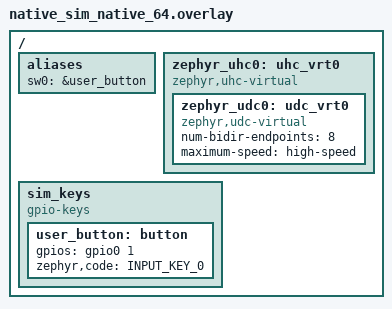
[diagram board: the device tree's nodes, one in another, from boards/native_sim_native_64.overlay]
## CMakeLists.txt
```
# hid8k-sim: hid8k's USB device code on native_sim, against Zephyr's own USB host stack on the
# virtual bus (drivers/usb/udc/udc_virtual.c, drivers/usb/uhc/uhc_virtual.c). See README.md.
# SPDX-License-Identifier: Apache-2.0

cmake_minimum_required(VERSION 3.20.0)

get_filename_component(HID8K_DIR ${CMAKE_CURRENT_LIST_DIR}/.. ABSOLUTE)

# The board's prj.conf first, so the simulation runs the firmware's own configuration (queue
# depth, HID buffer count, event queue sizes, logging), then the simulation's additions.
if(NOT DEFINED CONF_FILE)
  set(CONF_FILE "${HID8K_DIR}/prj.conf;${CMAKE_CURRENT_LIST_DIR}/prj.conf")
endif()

find_package(Zephyr REQUIRED HINTS $ENV{ZEPHYR_BASE})
project(hid8k_sim)

# The firmware, unchanged: the same four files the board build compiles.
target_sources(app PRIVATE
  ${HID8K_DIR}/src/main.c
  ${HID8K_DIR}/src/hid8k.c
  ${HID8K_DIR}/src/cdc_console.c
  ${HID8K_DIR}/src/usb_device.c
)

# The host side: two small class drivers for Zephyr's host stack and the test.
target_sources(app PRIVATE
  src/host_hid.c
  src/host_cdc.c
  src/sim_main.c
)

target_include_directories(app PRIVATE
  ${HID8K_DIR}/src
  ${ZEPHYR_BASE}/subsys/usb/host
  ${ZEPHYR_BASE}/drivers/usb/uhc
)

# The same warnings as the board build (see ../CMakeLists.txt).
target_compile_options(app PRIVATE -Wextra -Wshadow -Wno-type-limits)

if(CONFIG_HID8K_SIM_UHC_HS_FIX)
  # A copy of Zephyr v4.5.0's virtual host controller with its microframe timer kept after a bus
  # reset (drivers/uhc_virtual_hs.c says what changed and why).
  target_sources(app PRIVATE drivers/uhc_virtual_hs.c)
  target_include_directories(app PRIVATE ${ZEPHYR_BASE}/drivers/usb)
  # Zephyr's code, built with Zephyr's warnings, not this app's stricter -Wextra.
  set_source_files_properties(drivers/uhc_virtual_hs.c PROPERTIES COMPILE_OPTIONS
    "-Wno-extra;-Wno-unused-parameter")
endif()
```

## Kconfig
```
# hid8k-sim: the simulation's own options. The firmware's options follow (../Kconfig).
# SPDX-License-Identifier: Apache-2.0

menu "hid8k simulation (native_sim)"

config HID8K_SIM_UHC_HS_FIX
	bool "Build the simulation's copy of the virtual host controller (125 us microframes)"
	help
	  Zephyr v4.5.0's virtual host controller starts its SOF timer at
	  125 us when a high-speed device connects, but every bus reset,
	  resume and SOF enable restarts it at 1 ms, and the host stack resets
	  the bus as the first step of enumeration. So with the stock driver a
	  high-speed device is polled once per 1 ms frame. With this option the
	  simulation builds drivers/uhc_virtual_hs.c instead (set
	  CONFIG_UHC_VIRTUAL=n with it: hs_fix.conf does both), which keeps the
	  period the device's speed calls for.

config HID8K_SIM_STREAM_S
	int "Seconds of undisturbed stream to check and capture"
	default 3
	help
	  The run-time option --hid8k_stream_s overrides it.

config HID8K_SIM_HOST_XFERS
	int "Interrupt IN transfers the host keeps queued on the HID endpoint"
	range 1 2
	default 1
	help
	  1, like Linux usbhid's single interrupt URB. 2 shows a limitation of
	  the virtual host controller: it schedules one transfer per endpoint
	  per frame and only advances the start frame of the one it schedules,
	  so a second transfer queued on the same endpoint misses its start
	  frame and waits until the 16-bit frame counter comes round again.

endmenu

rsource "../Kconfig"
```

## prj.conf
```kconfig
# hid8k-sim: added to ../prj.conf (the board's), see CMakeLists.txt.

CONFIG_HID8K_SIM=y

# Zephyr's USB host stack on the virtual host controller (devicetree: boards/).
CONFIG_USB_HOST_STACK=y
CONFIG_UHC_DRIVER=y
CONFIG_UHC_XFER_COUNT=32
CONFIG_UHC_BUF_COUNT=32
CONFIG_UHC_BUF_POOL_SIZE=8192
CONFIG_UVB_MAX_MESSAGES=64
CONFIG_USBH_STACK_SIZE=2048

# A 125 us timer needs a tick finer than native_sim's default 10 ms: one tick per microsecond,
# as Zephyr's own USB host test sets (tests/subsys/usb/host/Kconfig).
CONFIG_SYS_CLOCK_TICKS_PER_SEC=1000000

# The simulation checks what the board build leaves unchecked.
CONFIG_ASSERT=y

# The button (gpio-keys on the emulated GPIO, boards/).
CONFIG_GPIO_EMUL=y

# Logs go to stdout, deferred as on the board (native_sim would default to immediate); keep the
# host stack quiet unless something is wrong.
CONFIG_LOG_MODE_DEFERRED=y
CONFIG_USBH_LOG_LEVEL_WRN=y
CONFIG_UHC_DRIVER_LOG_LEVEL_WRN=y

# Run as fast as the host allows, not in real time (native_sim's default for a non-test app).
CONFIG_NATIVE_SIM_SLOWDOWN_TO_REAL_TIME=n
```

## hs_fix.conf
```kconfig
# hid8k-sim with 125 us microframes: build the simulation's copy of the virtual host controller
# (drivers/uhc_virtual_hs.c) instead of Zephyr's. Use with -DEXTRA_CONF_FILE=hs_fix.conf.
CONFIG_UHC_VIRTUAL=n
CONFIG_HID8K_SIM_UHC_HS_FIX=y
```

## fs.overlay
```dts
/*
 * hid8k-sim, full-speed variant: the virtual device controller limited to full speed, which is
 * how the firmware sees a full-speed-only port, hub or cable at the bench. Use with
 * -DEXTRA_DTC_OVERLAY_FILE=fs.overlay. The firmware then builds no high-speed configuration,
 * streams at 1 ms, and must say so: "fs" on its stats line, the high-speed flag clear in every
 * report, and the host tool's verdict FAIL with "FULL speed".
 *
 * SPDX-License-Identifier: Apache-2.0
 */

&zephyr_udc0 {
	maximum-speed = "full-speed";
};
```

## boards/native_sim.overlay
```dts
/*
 * hid8k-sim on 32-bit native_sim (the default native_sim target, built with gcc -m32: the host
 * needs gcc-multilib): the same virtual controllers, button and USB nodes as the 64-bit target.
 *
 * SPDX-License-Identifier: Apache-2.0
 */

#include "native_sim_native_64.overlay"
```

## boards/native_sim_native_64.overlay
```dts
/*
 * hid8k-sim on native_sim/native/64: Zephyr's virtual USB host controller with the virtual device
 * controller on its bus, as Zephyr's own host test wires them (tests/subsys/usb/host/boards/), at
 * high speed; a button on the emulated GPIO for sw0; and the firmware's HID and CDC ACM nodes from
 * the same file the board overlay uses.
 *
 * SPDX-License-Identifier: Apache-2.0
 */

#include <zephyr/dt-bindings/gpio/gpio.h>
#include <zephyr/dt-bindings/input/input-event-codes.h>

/delete-node/ &zephyr_udc0;

/ {
	aliases {
		sw0 = &user_button;
	};

	zephyr_uhc0: uhc_vrt0 {
		compatible = "zephyr,uhc-virtual";

		zephyr_udc0: udc_vrt0 {
			compatible = "zephyr,udc-virtual";
			num-bidir-endpoints = <8>;
			maximum-speed = "high-speed";
		};
	};

	sim_keys: sim_keys {
		compatible = "gpio-keys";

		/* The Nucleo's USER button is active high with INPUT_KEY_0; so is this one. */
		user_button: button {
			gpios = <&gpio0 1 GPIO_ACTIVE_HIGH>;
			zephyr,code = <INPUT_KEY_0>;
		};
	};
};

#include "../../dts/hid8k_usb.dtsi"
```

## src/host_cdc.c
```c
/*
 * hid8k-sim: a minimal CDC ACM host class driver for Zephyr's USB host stack (v4.5.0 has none).
 * It binds to the CDC ACM function (its Interface Association), keeps one bulk IN transfer
 * queued on the data interface, splits what arrives into lines, and sends command lines on the
 * bulk OUT endpoint. The firmware's numbered filler lines (heavy mode, "~fill %08x ....") are
 * checked for length and numbering and counted, not kept; other lines go into a ring the test
 * searches, with the byte count of the stream at the end of each line.
 *
 * Every line is checked to be a whole firmware line: the console drops whole lines when its ring
 * is full, never part of one (cdc_console_write()), so a filler line of the wrong length, a line
 * with "~fill" or a second "hid8k" inside it, a line that does not start with "hid8k " or
 * "~fill ", or a stats line that does not end in its "pend=" field (and an optional note) means
 * a cut line. The first line after a reconnect is not judged: the bytes the device had queued
 * at the disconnect are lost with the configuration, so it may start in the middle.
 *
 * The completion callbacks run in the host stack's cooperative "usbh" thread.
 *
 * SPDX-License-Identifier: Apache-2.0
 */

#include <errno.h>
#include <stdlib.h>
#include <string.h>

#include <zephyr/kernel.h>
#include <zephyr/logging/log.h>
#include <zephyr/sys/byteorder.h>
#include <zephyr/sys/util.h>
#include <zephyr/usb/class/usb_cdc.h>
#include <zephyr/usb/usb_ch9.h>
#include <zephyr/usb/usbh.h>

#include <nsi_host_trampolines.h>

#include <usbh_class.h>
#include <usbh_class_api.h>
#include <usbh_desc.h>
#include <usbh_device.h>

#include "sim.h"

LOG_MODULE_REGISTER(sim_cdc, LOG_LEVEL_INF);

/* The firmware's filler lines: 64 bytes with CR LF (main.c, FILL_LINE_LEN). */
#define FILL_LEN   62U
#define LINE_MAX   1100U
#define RING_LINES 128U
#define RX_SIZE    2048U

static struct {
	struct sim_cdc_info info;
	struct usb_device *udev;
	struct uhc_transfer *rx_xfer;
	bool reading;
	char cur[LINE_MAX + 1U];
	size_t cur_len;
	bool cur_overflow;
	uint32_t line_no;
	bool have_fill;
	uint32_t next_fill;
	struct {
		uint32_t no;
		uint32_t bytes_end;
		char text[LINE_MAX + 1U];
	} ring[RING_LINES];
	uint32_t pos;       /* bytes of the stream so far */
	bool resync;        /* the next line follows a reconnect: not judged */
	uint32_t ring_head; /* next slot */
	struct sim_cdc_stats st;
	int log_fd;
} cdc = {
	.log_fd = -1,
};

static void keep_line(const char *const text)
{
	const uint32_t slot = cdc.ring_head % RING_LINES;

	cdc.ring[slot].no = cdc.line_no;
	cdc.ring[slot].bytes_end = cdc.pos;
	strncpy(cdc.ring[slot].text, text, LINE_MAX);
	cdc.ring[slot].text[LINE_MAX] = '\0';
	cdc.ring_head++;
}

/* A stats line ends with "pend=<n>" and at most one of format_stats()'s notes (main.c). */
static bool stats_line_whole(const char *const s)
{
	static const char *const notes[] = {"", " CYCCNT-MISMATCH", " NO-COMPLETIONS",
					    " not-streaming"};
	const char *p = strstr(s, " pend=");
	const char *q;

	if (p == NULL) {
		return false;
	}
	while ((q = strstr(p + 1, " pend=")) != NULL) {
		p = q;
	}
	p += 6;
	if (*p < '0' || *p > '9') {
		return false;
	}
	while (*p >= '0' && *p <= '9') {
		p++;
	}
	for (size_t i = 0; i < ARRAY_SIZE(notes); i++) {
		if (strcmp(p, notes[i]) == 0) {
			return true;
		}
	}

	return false;
}

static void end_line(void)
{
	char *const s = cdc.cur;
	size_t n = cdc.cur_len;
	const bool judge = !cdc.resync;

	if (n > 0U && s[n - 1U] == '\r') {
		n--;
	}
	s[n] = '\0';

	cdc.st.lines++;
	cdc.resync = false;

	if (strncmp(s, "~fill ", 6) == 0) {
		char *endp;
		const unsigned long no = strtoul(&s[6], &endp, 16);
		bool ok = (n == FILL_LEN) && (endp == &s[14]) && (*endp == ' ');

		for (size_t i = 15U; ok && i < n; i++) {
			ok = (s[i] == '.');
		}
		if (!ok && judge) {
			cdc.st.fill_bad++;
			sim_anomaly("bad filler line (%zu chars): %.40s", n, s);
		}
		if (cdc.have_fill && (uint32_t)no != cdc.next_fill) {
			/* Counted, and judged by the test (the console drops whole lines by design). */
			cdc.st.fill_breaks++;
			if ((uint32_t)no > cdc.next_fill) {
				cdc.st.fill_missing += (uint32_t)no - cdc.next_fill;
			}
			if (cdc.st.fill_breaks <= 8U) {
				sim_print("  note: CDC filler line %08lx after %08x\n", no,
					  cdc.next_fill - 1U);
			}
		}
		cdc.have_fill = true;
		cdc.next_fill = (uint32_t)no + 1U;
		cdc.st.fill_lines++;
	} else {
		if (strncmp(s, "hid8k t=", 8) == 0) {
			cdc.st.stats_lines++;
		}
		if (cdc.cur_overflow) {
			sim_anomaly("CDC line longer than %u bytes", LINE_MAX);
		}
		if (judge && (strstr(s, "~fill") != NULL || strncmp(s, "hid8k ", 6) != 0 ||
			      strstr(&s[6], "hid8k") != NULL ||
			      (strncmp(s, "hid8k t=", 8) == 0 && !stats_line_whole(s)))) {
			cdc.st.line_bad++;
			sim_anomaly("CDC line is not a whole firmware line (%zu chars): %.60s", n,
				    s);
		}
		keep_line(s);
	}

	cdc.line_no++;
	cdc.cur_len = 0U;
	cdc.cur_overflow = false;
}

static void rx_bytes(const uint8_t *const data, const size_t len)
{
	if (cdc.log_fd >= 0 && nsi_host_write(cdc.log_fd, data, len) != (long)len) {
		sim_anomaly("CDC log write failed");
	}

	for (size_t i = 0; i < len; i++) {
		cdc.pos++;
		if (data[i] == '\n') {
			end_line();
		} else if (cdc.cur_len < LINE_MAX) {
			cdc.cur[cdc.cur_len++] = (char)data[i];
		} else {
			cdc.cur_overflow = true;
		}
	}
}

static int rx_cb(struct usb_device *const udev, struct uhc_transfer *const xfer);

static int rx_submit(void)
{
	struct uhc_transfer *xfer;
	struct net_buf *buf;
	int ret;

	if (cdc.udev == NULL || cdc.rx_xfer != NULL) {
		return -EINVAL;
	}

	xfer = usbh_xfer_alloc(cdc.udev, cdc.info.ep_in, rx_cb, NULL);
	if (xfer == NULL) {
		sim_anomaly("CDC: no transfer");
		return -ENOMEM;
	}

	buf = usbh_xfer_buf_alloc(cdc.udev, RX_SIZE);
	if (buf == NULL) {
		(void)uhc_xfer_unref(xfer);
		sim_anomaly("CDC: no buffer");
		return -ENOMEM;
	}

	ret = usbh_xfer_buf_add(cdc.udev, xfer, buf);
	if (ret == 0) {
		ret = usbh_xfer_enqueue(cdc.udev, xfer);
	}
	if (ret != 0) {
		net_buf_unref(buf);
		(void)uhc_xfer_unref(xfer);
		return ret;
	}

	cdc.rx_xfer = xfer;

	return 0;
}

static int rx_cb(struct usb_device *const udev, struct uhc_transfer *const xfer)
{
	struct net_buf *buf = xfer->buf;
	const int err = xfer->err;

	ARG_UNUSED(udev);

	if (cdc.rx_xfer == xfer) {
		cdc.rx_xfer = NULL;
	}

	if (err == 0 && buf != NULL) {
		cdc.st.rx_transfers++;
		if (buf->len == 0U) {
			cdc.st.zlp++;
		} else {
			cdc.st.rx_bytes += buf->len;
			rx_bytes(buf->data, buf->len);
		}
	} else if (err != -ECONNRESET) {
		cdc.st.xfer_err++;
		sim_anomaly("CDC IN transfer error %d", err);
	}

	if (buf != NULL) {
		net_buf_unref(buf);
	}
	(void)uhc_xfer_unref(xfer);

	if (cdc.reading && cdc.udev != NULL && err != -ECONNRESET) {
		(void)rx_submit();
	}

	return 0;
}

static int tx_cb(struct usb_device *const udev, struct uhc_transfer *const xfer)
{
	ARG_UNUSED(udev);

	if (xfer->err != 0) {
		cdc.st.xfer_err++;
		sim_anomaly("CDC OUT transfer error %d", xfer->err);
	}

	if (xfer->buf != NULL) {
		net_buf_unref(xfer->buf);
	}
	(void)uhc_xfer_unref(xfer);

	return 0;
}

static int cdc_class_init(struct usbh_class_data *const c_data)
{
	ARG_UNUSED(c_data);

	return 0;
}

static int cdc_class_probe(struct usbh_class_data *const c_data, struct usb_device *const udev,
			   const uint8_t iface)
{
	const struct usb_cfg_descriptor *const cfg = udev->cfg_desc;
	const struct usb_association_descriptor *iad;
	const uint8_t *p;
	const uint8_t *end;
	struct sim_cdc_info info = {0};
	int cur_if = -1;

	ARG_UNUSED(c_data);

	iad = usbh_desc_get_iad(udev, iface);
	if (iad == NULL || iad->bFunctionClass != USB_BCC_CDC_CONTROL || iad->bInterfaceCount != 2U) {
		return -ENOTSUP;
	}

	info.iad_class = iad->bFunctionClass;
	info.iad_sub = iad->bFunctionSubClass;
	info.iad_proto = iad->bFunctionProtocol;
	info.comm_iface = iad->bFirstInterface;

	/* Walk the function's two interfaces and their endpoints. */
	p = (const uint8_t *)iad + iad->bLength;
	end = (const uint8_t *)cfg + cfg->wTotalLength;
	while (p + 2 <= end && p[0] >= 2U && p[1] != USB_DESC_INTERFACE_ASSOC) {
		if (p[1] == USB_DESC_INTERFACE) {
			const struct usb_if_descriptor *const if_d = (const void *)p;

			if (if_d->bInterfaceNumber != iad->bFirstInterface &&
			    if_d->bInterfaceNumber != iad->bFirstInterface + 1U) {
				break;
			}
			cur_if = if_d->bInterfaceNumber;
			if (if_d->bInterfaceClass == USB_BCC_CDC_DATA) {
				info.data_iface = if_d->bInterfaceNumber;
			}
		} else if (p[1] == USB_DESC_ENDPOINT && cur_if >= 0) {
			const struct usb_ep_descriptor *const ep = (const void *)p;
			const uint8_t type = ep->bmAttributes & USB_EP_TRANSFER_TYPE_MASK;

			if (type == USB_EP_TYPE_INTERRUPT && USB_EP_DIR_IS_IN(ep->bEndpointAddress)) {
				info.ep_notify = ep->bEndpointAddress;
				info.mps_notify = ep->wMaxPacketSize;
				info.notify_interval = ep->bInterval;
			} else if (type == USB_EP_TYPE_BULK &&
				   USB_EP_DIR_IS_IN(ep->bEndpointAddress)) {
				info.ep_in = ep->bEndpointAddress;
				info.mps_in = ep->wMaxPacketSize;
			} else if (type == USB_EP_TYPE_BULK) {
				info.ep_out = ep->bEndpointAddress;
				info.mps_out = ep->wMaxPacketSize;
			}
		}
		p += p[0];
	}

	if (info.ep_in == 0U || info.ep_out == 0U) {
		LOG_ERR("CDC function at interface %u has no bulk endpoints", iface);
		return -ENOTSUP;
	}

	info.bound = true;
	info.binds = cdc.info.binds + 1U;
	info.removals = cdc.info.removals;
	cdc.info = info;
	cdc.udev = udev;

	sim_print("  host: CDC ACM interfaces %u+%u bound: bulk IN 0x%02x (%u), OUT 0x%02x (%u)\n",
		info.comm_iface, info.data_iface, info.ep_in, info.mps_in, info.ep_out,
		info.mps_out);

	return 0;
}

static int cdc_class_removed(struct usbh_class_data *const c_data)
{
	ARG_UNUSED(c_data);

	if (cdc.rx_xfer != NULL && cdc.udev != NULL) {
		(void)usbh_xfer_dequeue(cdc.udev, cdc.rx_xfer);
	}

	cdc.udev = NULL;
	cdc.info.bound = false;
	cdc.info.removals++;
	/* A line cut by the disconnect is not a line, and the next one may start in the middle. */
	cdc.cur_len = 0U;
	cdc.cur_overflow = false;
	cdc.resync = true;
	sim_print("  host: CDC ACM class removed\n");

	return 0;
}

static struct usbh_class_api cdc_class_api = {
	.init = cdc_class_init,
	.probe = cdc_class_probe,
	.removed = cdc_class_removed,
};

static const struct usbh_class_filter cdc_filters[] = {
	{
		.class = USB_BCC_CDC_CONTROL,
		.sub = ACM_SUBCLASS,
		.proto = 0,
		.flags = USBH_CLASS_MATCH_CODE_TRIPLE,
	},
	{0},
};

USBH_DEFINE_CLASS(sim_hid8k_cdc, &cdc_class_api, NULL, cdc_filters);

bool sim_cdc_bound(void)
{
	return cdc.info.bound;
}

const struct sim_cdc_info *sim_cdc_info(void)
{
	return &cdc.info;
}

int sim_cdc_start(void)
{
	cdc.reading = true;

	return cdc.rx_xfer == NULL ? rx_submit() : 0;
}

void sim_cdc_stop(void)
{
	cdc.reading = false;
}

int sim_cdc_send(const char *const line)
{
	const size_t len = strlen(line);
	struct uhc_transfer *xfer;
	struct net_buf *buf;
	int ret;

	if (cdc.udev == NULL) {
		return -ENODEV;
	}

	xfer = usbh_xfer_alloc(cdc.udev, cdc.info.ep_out, tx_cb, NULL);
	if (xfer == NULL) {
		return -ENOMEM;
	}

	buf = usbh_xfer_buf_alloc(cdc.udev, len + 2U);
	if (buf == NULL) {
		(void)uhc_xfer_unref(xfer);
		return -ENOMEM;
	}

	net_buf_add_mem(buf, line, len);
	net_buf_add_mem(buf, "\r\n", 2U);

	ret = usbh_xfer_buf_add(cdc.udev, xfer, buf);
	if (ret == 0) {
		ret = usbh_xfer_enqueue(cdc.udev, xfer);
	}
	if (ret != 0) {
		net_buf_unref(buf);
		(void)uhc_xfer_unref(xfer);
		return ret;
	}

	cdc.st.tx_bytes += len + 2U;

	return 0;
}

void sim_cdc_stats(struct sim_cdc_stats *const out)
{
	*out = cdc.st;
}

uint32_t sim_cdc_line_count(void)
{
	return cdc.line_no;
}

bool sim_cdc_find(uint32_t *const from, const char *const needle, char *const out,
		  const size_t out_len)
{
	return sim_cdc_find_at(from, needle, out, out_len, NULL);
}

bool sim_cdc_find_at(uint32_t *const from, const char *const needle, char *const out,
		     const size_t out_len, uint32_t *const bytes_end)
{
	const uint32_t n = MIN(cdc.ring_head, RING_LINES);

	/* Oldest first. */
	for (uint32_t k = 0; k < n; k++) {
		const uint32_t slot = (cdc.ring_head - n + k) % RING_LINES;

		if (cdc.ring[slot].no < *from || strstr(cdc.ring[slot].text, needle) == NULL) {
			continue;
		}
		if (out != NULL && out_len > 0U) {
			strncpy(out, cdc.ring[slot].text, out_len - 1U);
			out[out_len - 1U] = '\0';
		}
		*from = cdc.ring[slot].no + 1U;
		if (bytes_end != NULL) {
			*bytes_end = cdc.ring[slot].bytes_end;
		}
		return true;
	}

	return false;
}

void sim_cdc_log(const int fd)
{
	cdc.log_fd = fd;
}
```

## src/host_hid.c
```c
/*
 * hid8k-sim: a minimal HID host class driver for Zephyr's USB host stack. Zephyr v4.5.0 has none
 * (subsys/usb/host/class/ holds only a hub and a UVC driver), so this one binds to the HID
 * interface, keeps CONFIG_HID8K_SIM_HOST_XFERS interrupt IN transfers queued (1 by default, the
 * way Linux usbhid keeps one interrupt URB), and checks every report as it arrives:
 *
 *   - the report ID and length (ID 1: 30 bytes; ID 2: 64), the stats format, queue depth,
 *     cycle-counter rate and flags;
 *   - sequence continuity: every report on the endpoint (IDs 1 and 2) takes one seq, so a stats
 *     report's seq must be the previous report's seq + 1;
 *   - the pacing: in steady state a stats report names the completion DEPTH reports before it
 *     (seq - done_seq == CONFIG_HID8K_QUEUE_DEPTH), and consecutive completions are one frame
 *     apart on the device's clock;
 *   - the age of each report when the host takes it (arrival - t_submit; the simulation has one
 *     clock, so this is exact).
 *
 * It can also stop and restart polling, which is how a host that stops reading looks to the
 * device, and capture every report to a host file for host/hid8k_analysis.py.
 *
 * The completion callback runs in the host stack's cooperative "usbh" thread.
 *
 * SPDX-License-Identifier: Apache-2.0
 */

#include <errno.h>
#include <string.h>

#include <zephyr/kernel.h>
#include <zephyr/logging/log.h>
#include <zephyr/sys/byteorder.h>
#include <zephyr/sys/util.h>
#include <zephyr/usb/class/hid.h>
#include <zephyr/usb/usb_ch9.h>
#include <zephyr/usb/usbh.h>

#include <nsi_host_trampolines.h>

#include <usbh_class.h>
#include <usbh_class_api.h>
#include <usbh_desc.h>
#include <usbh_device.h>

#include "hid8k_report.h"
#include "sim.h"

LOG_MODULE_REGISTER(sim_hid, LOG_LEVEL_INF);

#define DEPTH CONFIG_HID8K_QUEUE_DEPTH
#define NXFERS CONFIG_HID8K_SIM_HOST_XFERS

/* One capture record: arrival time, length, then the report (zero padded), 80 bytes. */
struct capture_rec {
	uint64_t arrival_ns;
	uint16_t len;
	uint16_t rsvd0;
	uint32_t rsvd1;
	uint8_t data[64];
} __packed;
BUILD_ASSERT(sizeof(struct capture_rec) == 80, "capture record layout (sim_capture.py)");

#define CAPTURE_BATCH 256

static struct {
	struct sim_hid_info info;
	struct usb_device *udev;
	struct uhc_transfer *xfer[NXFERS];
	bool polling;
	/* Stream state. */
	bool have_prev;
	uint32_t next_seq;    /* the seq the next report should have */
	bool have_done;
	uint32_t prev_done_seq;
	uint32_t prev_t_done;
	uint32_t since_restart; /* reports since the stream (re)started */
	struct sim_hid_stats st;
	/* Capture. */
	int cap_fd;
	uint32_t captured;
	unsigned int cap_n;
	struct capture_rec cap[CAPTURE_BATCH];
} hid = {
	.cap_fd = -1,
};

static void stats_clear(struct sim_hid_stats *s)
{
	memset(s, 0, sizeof(*s));
	s->ival_min = UINT32_MAX;
	s->age_min = UINT32_MAX;
	s->gap_min_us = INT64_MAX;
}

static void capture_write(void)
{
	if (hid.cap_fd >= 0 && hid.cap_n > 0U) {
		const long want = (long)(hid.cap_n * sizeof(struct capture_rec));

		if (nsi_host_write(hid.cap_fd, hid.cap, (unsigned long)want) != want) {
			sim_anomaly("capture write failed");
		}
	}
	hid.cap_n = 0U;
}

static void capture(const uint8_t *data, const uint16_t len, const int64_t now_us)
{
	struct capture_rec *r;

	if (hid.cap_fd < 0) {
		return;
	}

	r = &hid.cap[hid.cap_n++];
	memset(r, 0, sizeof(*r));
	r->arrival_ns = (uint64_t)now_us * 1000U;
	r->len = MIN(len, sizeof(r->data));
	memcpy(r->data, data, r->len);
	hid.captured++;
	if (hid.cap_n == CAPTURE_BATCH) {
		capture_write();
	}
}

/* One report off the bus. */
static void check_report(const uint8_t *const d, const uint16_t len, const int64_t now_us)
{
	struct sim_hid_stats *const s = &hid.st;
	const uint32_t now_cyc = (uint32_t)now_us; /* 1 MHz: cycles == us */
	uint32_t seq;

	capture(d, len, now_us);
	s->transfers++;

	if (s->last_arrival_us != 0) {
		const int64_t gap = now_us - s->last_arrival_us;

		s->gap_n++;
		s->gap_min_us = MIN(s->gap_min_us, gap);
		s->gap_max_us = MAX(s->gap_max_us, gap);
	}
	s->last_arrival_us = now_us;

	if (len == HID8K_KBD_SIZE && d[0] == HID8K_REPORT_ID_KBD) {
		const bool f24 = (d[2U + HID8K_KEY_F24 / 8U] & BIT(HID8K_KEY_F24 % 8U)) != 0U;
		bool others = d[1] != 0U;

		for (unsigned int i = 2; i < HID8K_KBD_SIZE; i++) {
			const uint8_t mask = (i == 2U + HID8K_KEY_F24 / 8U) ?
					     (uint8_t)~BIT(HID8K_KEY_F24 % 8U) : 0xFFU;

			others |= (d[i] & mask) != 0U;
		}
		if (others) {
			sim_anomaly("keyboard report with keys other than F24");
			s->bad++;
		}
		s->kbd++;
		if (f24) {
			s->kbd_f24_down++;
		} else {
			s->kbd_f24_up++;
		}
		/* A keyboard report takes one seq; it carries none. */
		if (hid.have_prev) {
			hid.next_seq++;
		}
		hid.since_restart++;
		return;
	}

	if (len != HID8K_STATS_SIZE || d[HID8K_OFF_ID] != HID8K_REPORT_ID_STATS) {
		sim_anomaly("unexpected report: ID %u, %u bytes", d[0], len);
		s->bad++;
		return;
	}

	if (d[HID8K_OFF_FORMAT] != HID8K_FORMAT || d[HID8K_OFF_DEPTH] != DEPTH ||
	    sys_get_le32(&d[HID8K_OFF_CPU_HZ]) != CONFIG_SYS_CLOCK_HW_CYCLES_PER_SEC ||
	    (d[HID8K_OFF_FLAGS] & HID8K_FLAG_FN_VALID) != 0U ||
	    ((d[HID8K_OFF_FLAGS] & HID8K_FLAG_HIGH_SPEED) != 0U) !=
		    (hid.udev != NULL && hid.udev->speed == USB_SPEED_SPEED_HS)) {
		sim_anomaly("stats report fields: format %u depth %u cpu_hz %u flags 0x%02x",
			    d[HID8K_OFF_FORMAT], d[HID8K_OFF_DEPTH],
			    sys_get_le32(&d[HID8K_OFF_CPU_HZ]), d[HID8K_OFF_FLAGS]);
		s->bad++;
	}

	seq = sys_get_le32(&d[HID8K_OFF_SEQ]);
	if (s->stats == 0U) {
		s->first_seq = seq;
		s->first_done_seq = sys_get_le32(&d[HID8K_OFF_DONE_SEQ]);
	}
	s->stats++;
	s->last_seq = seq;

	if (hid.have_prev && seq != hid.next_seq) {
		sim_anomaly("seq %u after %u (expected %u)", seq, hid.next_seq - 1U, hid.next_seq);
		s->seq_breaks++;
	}
	hid.have_prev = true;
	hid.next_seq = seq + 1U;
	hid.since_restart++;

	/* Pacing: steady state starts once the priming reports are through. */
	{
		const uint32_t done_seq = sys_get_le32(&d[HID8K_OFF_DONE_SEQ]);
		const uint32_t t_done = sys_get_le32(&d[HID8K_OFF_T_DONE]);
		const uint32_t t_submit = sys_get_le32(&d[HID8K_OFF_T_SUBMIT]);
		const uint32_t age = now_cyc - t_submit;

		/*
		 * In steady state a report is built when the one DEPTH before it completes. Right
		 * after the queue is primed (a new configuration) or refilled from empty (the refill
		 * kick), the first reports are built back to back and name an older completion: a
		 * shorter lag, counted, not an anomaly. 0 or more than DEPTH never happens.
		 */
		if (hid.since_restart > DEPTH) {
			const uint32_t lag = seq - done_seq;

			if (lag > 0U && lag < DEPTH) {
				s->lag_short++;
			} else if (lag != DEPTH) {
				s->lag_bad++;
				sim_anomaly("seq %u names completion %u (lag %u, depth %u)", seq,
					    done_seq, lag, DEPTH);
			}
		}

		if (hid.have_done && done_seq == hid.prev_done_seq + 1U) {
			const uint32_t ival = t_done - hid.prev_t_done;

			s->ival_n++;
			s->ival_sum += ival;
			s->ival_min = MIN(s->ival_min, ival);
			s->ival_max = MAX(s->ival_max, ival);
		}
		hid.have_done = true;
		hid.prev_done_seq = done_seq;
		hid.prev_t_done = t_done;

		s->age_min = MIN(s->age_min, age);
		s->age_max = MAX(s->age_max, age);
	}

	s->refused = sys_get_le32(&d[HID8K_OFF_REFUSED]);
	s->busy = sys_get_le32(&d[HID8K_OFF_BUSY]);
	s->late = sys_get_le32(&d[HID8K_OFF_LATE]);
	s->kbd_count = sys_get_le32(&d[HID8K_OFF_KBD_COUNT]);
	s->uptime_ms = sys_get_le32(&d[HID8K_OFF_UPTIME_MS]);
	s->cdc_bytes = sys_get_le32(&d[HID8K_OFF_CDC_BYTES]);
	s->cdc_dropped = sys_get_le32(&d[HID8K_OFF_CDC_DROPPED]);
	s->flags = d[HID8K_OFF_FLAGS];
}

static int hid_in_cb(struct usb_device *const udev, struct uhc_transfer *const xfer);

/* Queue one interrupt IN transfer in slot i. */
static int submit(const unsigned int i)
{
	struct uhc_transfer *xfer;
	struct net_buf *buf;
	int ret;

	if (hid.udev == NULL || hid.xfer[i] != NULL) {
		return -EINVAL;
	}

	xfer = usbh_xfer_alloc(hid.udev, hid.info.ep, hid_in_cb, (void *)(uintptr_t)i);
	if (xfer == NULL) {
		sim_anomaly("HID: no transfer");
		return -ENOMEM;
	}

	buf = usbh_xfer_buf_alloc(hid.udev, hid.info.ep_mps);
	if (buf == NULL) {
		(void)uhc_xfer_unref(xfer);
		sim_anomaly("HID: no buffer");
		return -ENOMEM;
	}

	ret = usbh_xfer_buf_add(hid.udev, xfer, buf);
	if (ret == 0) {
		ret = usbh_xfer_enqueue(hid.udev, xfer);
	}
	if (ret != 0) {
		net_buf_unref(buf);
		(void)uhc_xfer_unref(xfer);
		sim_anomaly("HID: enqueue failed %d", ret);
		return ret;
	}

	hid.xfer[i] = xfer;

	return 0;
}

static int hid_in_cb(struct usb_device *const udev, struct uhc_transfer *const xfer)
{
	const unsigned int i = (unsigned int)(uintptr_t)xfer->priv;
	struct net_buf *buf = xfer->buf;
	const int err = xfer->err;
	const int64_t now = sim_now_us();

	ARG_UNUSED(udev);

	if (i < NXFERS && hid.xfer[i] == xfer) {
		hid.xfer[i] = NULL;
		if (err == 0 && i < ARRAY_SIZE(hid.st.per_slot)) {
			hid.st.per_slot[i]++;
		}
	}

	if (err == -ECONNRESET) {
		hid.st.cancelled++;
	} else if (err != 0) {
		hid.st.xfer_err++;
		sim_anomaly("HID transfer error %d", err);
	} else if (buf == NULL || buf->len == 0U) {
		hid.st.zero_len++;
	} else {
		check_report(buf->data, buf->len, now);
	}

	if (buf != NULL) {
		net_buf_unref(buf);
	}
	(void)uhc_xfer_unref(xfer);

	if (hid.polling && hid.udev != NULL && err != -ECONNRESET && i < NXFERS) {
		(void)submit(i);
	}

	return 0;
}

static int hid_class_init(struct usbh_class_data *const c_data)
{
	ARG_UNUSED(c_data);

	stats_clear(&hid.st);

	return 0;
}

static int hid_class_probe(struct usbh_class_data *const c_data, struct usb_device *const udev,
			   const uint8_t iface)
{
	const struct usb_cfg_descriptor *const cfg = udev->cfg_desc;
	const struct usb_if_descriptor *if_d;
	const uint8_t *p;
	const uint8_t *end;
	struct sim_hid_info info = {0};

	ARG_UNUSED(c_data);

	if_d = usbh_desc_get_iface(udev, iface);
	if (if_d == NULL || if_d->bInterfaceClass != USB_BCC_HID) {
		return -ENOTSUP;
	}

	info.iface = iface;
	info.if_class = if_d->bInterfaceClass;
	info.if_sub = if_d->bInterfaceSubClass;
	info.if_proto = if_d->bInterfaceProtocol;
	info.if_num_ep = if_d->bNumEndpoints;

	/* The HID class descriptor and the endpoints follow the interface descriptor. */
	p = (const uint8_t *)if_d + if_d->bLength;
	end = (const uint8_t *)cfg + cfg->wTotalLength;
	while (p + 2 <= end && p[0] >= 2U && p[1] != USB_DESC_INTERFACE &&
	       p[1] != USB_DESC_INTERFACE_ASSOC) {
		if (p[1] == USB_DESC_HID && p[0] >= 9U) {
			info.bcd_hid = sys_get_le16(&p[2]);
			info.rdesc_type = p[6];
			info.rdesc_len = sys_get_le16(&p[7]);
		} else if (p[1] == USB_DESC_ENDPOINT && p[0] >= 7U && USB_EP_DIR_IS_IN(p[2])) {
			const struct usb_ep_descriptor *const ep = (const void *)p;

			info.ep = ep->bEndpointAddress;
			info.ep_attr = ep->bmAttributes;
			/* usbh already converted it to CPU order in place (usbh_device.c). */
			info.ep_mps = ep->wMaxPacketSize;
			info.ep_interval = ep->bInterval;
		}
		p += p[0];
	}

	if (info.ep == 0U) {
		LOG_ERR("HID interface %u has no IN endpoint", iface);
		return -ENOTSUP;
	}

	info.bound = true;
	info.binds = hid.info.binds + 1U;
	info.removals = hid.info.removals;
	hid.info = info;
	hid.udev = udev;

	sim_print("  host: HID interface %u bound: ep 0x%02x, wMaxPacketSize %u, bInterval %u\n",
		  iface, info.ep, info.ep_mps, info.ep_interval);

	return 0;
}

static int hid_class_removed(struct usbh_class_data *const c_data)
{
	ARG_UNUSED(c_data);

	for (unsigned int i = 0; i < NXFERS; i++) {
		if (hid.xfer[i] != NULL && hid.udev != NULL) {
			(void)usbh_xfer_dequeue(hid.udev, hid.xfer[i]);
		}
	}

	hid.udev = NULL;
	hid.info.bound = false;
	hid.info.removals++;
	sim_print("  host: HID class removed\n");

	return 0;
}

static struct usbh_class_api hid_class_api = {
	.init = hid_class_init,
	.probe = hid_class_probe,
	.removed = hid_class_removed,
};

static const struct usbh_class_filter hid_filters[] = {
	{
		.class = USB_BCC_HID,
		.sub = 0,
		.proto = 0,
		.flags = USBH_CLASS_MATCH_CODE_TRIPLE,
	},
	{0},
};

USBH_DEFINE_CLASS(sim_hid8k_hid, &hid_class_api, NULL, hid_filters);

bool sim_hid_bound(void)
{
	return hid.info.bound;
}

const struct sim_hid_info *sim_hid_info(void)
{
	return &hid.info;
}

struct usb_device *sim_hid_udev(void)
{
	return hid.udev;
}

int sim_hid_poll(const bool on)
{
	int ret = 0;

	hid.polling = on;
	if (on) {
		for (unsigned int i = 0; i < NXFERS; i++) {
			if (hid.xfer[i] == NULL) {
				ret = submit(i);
				if (ret != 0) {
					break;
				}
			}
		}
	}

	return ret;
}

bool sim_hid_polling(void)
{
	return hid.polling;
}

void sim_hid_stats(struct sim_hid_stats *const out, const bool clear)
{
	*out = hid.st;
	if (clear) {
		const int64_t last = hid.st.last_arrival_us;

		stats_clear(&hid.st);
		hid.st.last_arrival_us = last;
	}
}

void sim_hid_stream_restart(void)
{
	hid.have_prev = false;
	hid.have_done = false;
	hid.since_restart = 0U;
	hid.st.last_arrival_us = 0;
}

void sim_hid_capture(const int fd)
{
	capture_write();
	hid.cap_fd = fd;
}

uint32_t sim_hid_captured(void)
{
	return hid.captured;
}

void sim_hid_capture_flush(void)
{
	capture_write();
}
```

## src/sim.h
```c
/*
 * hid8k-sim: what the host-side files share. Everything here runs in cooperative threads (the
 * USB host stack's "usbh" thread for transfer completions, and the test thread), which never
 * interleave on native_sim's single CPU unless one blocks, so plain variables are enough.
 *
 * SPDX-License-Identifier: Apache-2.0
 */

#ifndef HID8K_SIM_H_
#define HID8K_SIM_H_

#include <stdbool.h>
#include <stddef.h>
#include <stdint.h>

#include <zephyr/usb/usbh.h>

/* The host controller and its context (sim_main.c). */
extern struct usbh_context *const sim_uhs_ctx;

/*
 * The test's own output: straight to the host's stdout (nsi_print_trace()), not through the
 * firmware's deferred log buffer, which drops messages when a burst outruns it. The firmware's
 * printk() and log messages still go through Zephyr's logging, as on the board, so they can
 * appear a little later than the test's lines.
 */
void sim_print(const char *fmt, ...) __printf_like(1, 2);

/* Simulated time, microseconds (native_sim: 1 MHz cycles and ticks). */
int64_t sim_now_us(void);

/* Report an anomaly seen by a class driver: printed (the first ones) and counted. */
void sim_anomaly(const char *fmt, ...);
uint32_t sim_anomalies(void);

/* ------------------------------------------------------------------ HID host class (host_hid.c) */

struct sim_hid_info {
	bool bound;
	uint8_t iface;
	uint8_t if_class, if_sub, if_proto, if_num_ep;
	uint16_t bcd_hid;
	uint8_t rdesc_type;
	uint16_t rdesc_len;
	uint8_t ep;          /* bEndpointAddress of the interrupt IN endpoint */
	uint8_t ep_attr;     /* bmAttributes */
	uint16_t ep_mps;     /* wMaxPacketSize */
	uint8_t ep_interval; /* bInterval */
	uint32_t binds;      /* times the class was bound (1 per enumeration) */
	uint32_t removals;
};

/* Stream checks, kept by the completion callback for every report. */
struct sim_hid_stats {
	uint32_t transfers;   /* completed IN transfers with data */
	uint32_t stats;       /* stats reports (ID 2) */
	uint32_t kbd;         /* keyboard reports (ID 1) */
	uint32_t kbd_f24_down;
	uint32_t kbd_f24_up;
	uint32_t bad;         /* wrong length, ID, format, depth, cpu_hz, flags */
	uint32_t xfer_err;    /* transfers that ended with an error other than a cancellation */
	uint32_t cancelled;
	uint32_t zero_len;
	uint32_t per_slot[2]; /* completed transfers per queued-transfer slot (HOST_XFERS) */
	uint32_t seq_breaks;  /* a report whose seq is not the previous one + 1 */
	uint32_t lag_short;   /* seq - done_seq below the depth: the queue was refilled from empty */
	uint32_t lag_bad;     /* seq - done_seq of 0 or above the depth: should never happen */
	uint32_t first_seq, last_seq;
	uint32_t first_done_seq; /* done_seq of the first stats report since the last clear */
	/* Device completion intervals from t_done, cycles: consecutive done_seq only. */
	uint32_t ival_n, ival_min, ival_max;
	uint64_t ival_sum;
	/* Host arrival minus t_submit (the same clock in the simulation), cycles. */
	uint32_t age_min, age_max;
	/* Host arrival intervals, us. */
	uint32_t gap_n;
	int64_t gap_min_us, gap_max_us;
	int64_t last_arrival_us;
	/* The latest stats report's counters. */
	uint32_t refused, busy, late, kbd_count, uptime_ms, cdc_bytes, cdc_dropped;
	uint8_t flags;
};

bool sim_hid_bound(void);
const struct sim_hid_info *sim_hid_info(void);
struct usb_device *sim_hid_udev(void);
/* Start or stop polling. Stopping lets the transfer in flight finish and queues no more. */
int sim_hid_poll(bool on);
bool sim_hid_polling(void);
/* Copy the statistics; clear them if asked (the stream checks continue across a clear). */
void sim_hid_stats(struct sim_hid_stats *out, bool clear);
/* Forget the previous report: the next one starts a new stream (after a reconnect). */
void sim_hid_stream_restart(void);
/* Capture every report to the host file (fd from nsi_host_open), or stop with -1. */
void sim_hid_capture(int fd);
uint32_t sim_hid_captured(void);
void sim_hid_capture_flush(void);

/* ------------------------------------------------------------ CDC ACM host class (host_cdc.c) */

struct sim_cdc_info {
	bool bound;
	uint8_t comm_iface, data_iface;
	uint8_t iad_class, iad_sub, iad_proto;
	uint8_t ep_notify, ep_in, ep_out;
	uint16_t mps_in, mps_out, mps_notify;
	uint8_t notify_interval;
	uint32_t binds;
	uint32_t removals;
};

struct sim_cdc_stats {
	uint32_t rx_bytes;
	uint32_t rx_transfers;
	uint32_t zlp;
	uint32_t lines;        /* complete lines received, filler included */
	uint32_t stats_lines;  /* lines starting "hid8k t=" */
	uint32_t fill_lines;
	uint32_t fill_breaks;  /* a filler line whose number is not the previous one + 1 */
	uint32_t fill_missing; /* filler lines missing at those breaks */
	uint32_t fill_bad;     /* a filler line of the wrong length or form */
	uint32_t line_bad;     /* another line that is not a whole firmware line (see host_cdc.c) */
	uint32_t tx_bytes;
	uint32_t xfer_err;
};

bool sim_cdc_bound(void);
const struct sim_cdc_info *sim_cdc_info(void);
/* Start reading the bulk IN endpoint. */
int sim_cdc_start(void);
/*
 * Stop reading it, as a host with the port closed does: the transfer in flight completes, no
 * more are queued, so the device's CDC buffers and the firmware's ring fill up.
 */
void sim_cdc_stop(void);
/* Send a command line (CR LF added) on the bulk OUT endpoint. */
int sim_cdc_send(const char *line);
void sim_cdc_stats(struct sim_cdc_stats *out);
/* Lines are numbered from 0 as they arrive (filler lines are counted, not kept). */
uint32_t sim_cdc_line_count(void);
/*
 * Find the first kept line at or after number *from that contains needle; copy it to out and set
 * *from past it. Lines older than the ring are gone.
 */
bool sim_cdc_find(uint32_t *from, const char *needle, char *out, size_t out_len);
/*
 * The same, also giving the byte count of the CDC stream (since the reader started) at the end
 * of that line, its CR LF included.
 */
bool sim_cdc_find_at(uint32_t *from, const char *needle, char *out, size_t out_len,
		     uint32_t *bytes_end);
/* Log every received byte to the host file (fd from nsi_host_open), or stop with -1. */
void sim_cdc_log(int fd);

#endif /* HID8K_SIM_H_ */
```
